# ATmega128RFA1 device description
Architecture: AVR8; Family: megaAVR
Registers are 8-bit, access not given, no defined reset value unless marked. A register's access mark holds for its fields unless they carry their own. Offsets are from the block's base; [hi:lo] are bit positions; 'fields as' and 'values as' point back to an identical list.

## TC1 (TC16 module) — Timer/Counter, 16-bit
Instances: TC1 0x00
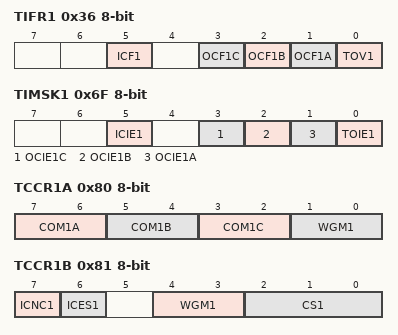
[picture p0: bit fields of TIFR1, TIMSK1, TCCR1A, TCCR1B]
0x36 TIFR1 — Timer/Counter1 Interrupt Flag Register
  [5] ICF1 — Timer/Counter1 Input Capture Flag
  [3] OCF1C — Timer/Counter1 Output Compare C Match Flag
  [2] OCF1B — Timer/Counter1 Output Compare B Match Flag
  [1] OCF1A — Timer/Counter1 Output Compare A Match Flag
  [0] TOV1 — Timer/Counter1 Overflow Flag
0x6F TIMSK1 — Timer/Counter1 Interrupt Mask Register
  [5] ICIE1 — Timer/Counter1 Input Capture Interrupt Enable
  [3] OCIE1C — Timer/Counter1 Output Compare C Match Interrupt Enable
  [2] OCIE1B — Timer/Counter1 Output Compare B Match Interrupt Enable
  [1] OCIE1A — Timer/Counter1 Output Compare A Match Interrupt Enable
  [0] TOIE1 — Timer/Counter1 Overflow Interrupt Enable
0x80 TCCR1A — Timer/Counter1 Control Register A
  [7:6] COM1A — Compare Output Mode for Channel A
    0=Normal port operation, OCnA/OCnB/OCnC disconnected; 1=Toggle OCnA/OCnB/OCnC on Compare Match; 2=Clear OCnA/OCnB/OCnC on Compare Match (set output to low level); 3=Set OCnA/OCnB/OCnC on Compare Match (set output to high level)
  [5:4] COM1B — Compare Output Mode for Channel B
    values as COM1A
  [3:2] COM1C — Compare Output Mode for Channel C
    values as COM1A
  [1:0] WGM1 — Waveform Generation Mode
    0=Normal mode of operation; 1=PWM, phase correct, 8-bit; 2=PWM, phase correct, 9-bit; 3=PWM, phase correct, 10-bit; 4=CTC, TOP = OCRnA; 5=Fast PWM, 8-bit; 6=Fast PWM, 9-bit; 7=Fast PWM, 10-bit; 8=PWM, Phase and frequency correct, TOP = ICRn; 9=PWM, Phase and frequency correct, TOP = OCRnA; 10=PWM, Phase correct, TOP = ICRn; 11=PWM, Phase correct, TOP = OCRnA; 12=CTC, TOP = OCRnA; 14=Fast PWM, TOP = ICRn; 15=Fast PWM, TOP = OCRnA
0x81 TCCR1B — Timer/Counter1 Control Register B
  [7] ICNC1 — Input Capture 1 Noise Canceller
  [6] ICES1 — Input Capture 1 Edge Select
  [4:3] WGM1 (bit 2 of the value upward) — Waveform Generation Mode
    values as TCCR1A.WGM1
  [2:0] CS1 — Clock Select
    0=No clock source (Timer/Counter stopped); 1=clk_IO/1 (no prescaling); 2=clk_IO/8 (from prescaler); 3=clk_IO/64 (from prescaler); 4=clk_IO/256 (from prescaler); 5=clk_IO/1024 (from prescaler); 6=External clock source on Tn pin, clock on falling edge; 7=External clock source on Tn pin, clock on rising edge
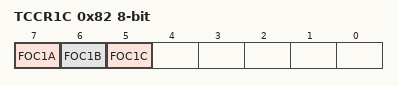
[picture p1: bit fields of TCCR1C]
0x82 TCCR1C — Timer/Counter1 Control Register C
  [7] FOC1A — Force Output Compare for Channel A
  [6] FOC1B — Force Output Compare for Channel B
  [5] FOC1C — Force Output Compare for Channel C
0x84 TCNT1 16-bit — Timer/Counter1 Bytes
0x86 ICR1 16-bit — Timer/Counter1 Input Capture Register Bytes
0x88 OCR1A 16-bit — Timer/Counter1 Output Compare Register A Bytes
0x8A OCR1B 16-bit — Timer/Counter1 Output Compare Register B Bytes
0x8C OCR1C 16-bit — Timer/Counter1 Output Compare Register C Bytes

## SYMCNT — MAC Symbol Counter
Instances: SYMCNT 0x00
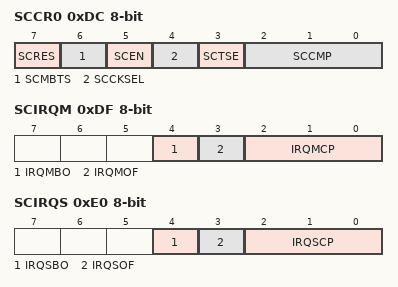
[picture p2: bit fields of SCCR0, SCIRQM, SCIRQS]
0xDC SCCR0 — Symbol Counter Control Register 0
  [7] SCRES — Symbol Counter Synchronization
  [6] SCMBTS — Manual Beacon Timestamp
  [5] SCEN — Symbol Counter enable
  [4] SCCKSEL — Symbol Counter Clock Source select
  [3] SCTSE — Symbol Counter Automatic Timestamping enable
  [2:0] SCCMP (bit 1 of the value upward) — Symbol Counter Compare Unit 3 Mode select
0xDD SCCR1 — Symbol Counter Control Register 1
  [0] SCENBO — Backoff Slot Counter enable
0xDE SCSR — Symbol Counter Status Register
  [0] SCBSY — Symbol Counter busy
0xDF SCIRQM — Symbol Counter Interrupt Mask Register
  [4] IRQMBO — Backoff Slot Counter IRQ enable
  [3] IRQMOF — Symbol Counter Overflow IRQ enable
  [2:0] IRQMCP (bit 1 of the value upward) — Symbol Counter Compare Match 3 IRQ enable
0xE0 SCIRQS — Symbol Counter Interrupt Status Register
  [4] IRQSBO — Backoff Slot Counter IRQ
  [3] IRQSOF — Symbol Counter Overflow IRQ
  [2:0] IRQSCP (bit 1 of the value upward) — Compare Unit 3 Compare Match IRQ
0xE1 SCCNTLL — Symbol Counter Register LL-Byte
0xE2 SCCNTLH — Symbol Counter Register LH-Byte
0xE3 SCCNTHL — Symbol Counter Register HL-Byte
0xE4 SCCNTHH — Symbol Counter Register HH-Byte
0xE5 SCBTSRLL — Symbol Counter Beacon Timestamp Register LL-Byte
0xE6 SCBTSRLH — Symbol Counter Beacon Timestamp Register LH-Byte
0xE7 SCBTSRHL — Symbol Counter Beacon Timestamp Register HL-Byte
0xE8 SCBTSRHH — Symbol Counter Beacon Timestamp Register HH-Byte
0xE9 SCTSRLL — Symbol Counter Frame Timestamp Register LL-Byte
0xEA SCTSRLH — Symbol Counter Frame Timestamp Register LH-Byte
0xEB SCTSRHL — Symbol Counter Frame Timestamp Register HL-Byte
0xEC SCTSRHH — Symbol Counter Frame Timestamp Register HH-Byte
0xED SCOCR3LL — Symbol Counter Output Compare Register 3 LL-Byte
0xEE SCOCR3LH — Symbol Counter Output Compare Register 3 LH-Byte
0xEF SCOCR3HL — Symbol Counter Output Compare Register 3 HL-Byte
0xF0 SCOCR3HH — Symbol Counter Output Compare Register 3 HH-Byte
0xF1 SCOCR2LL — Symbol Counter Output Compare Register 2 LL-Byte
0xF2 SCOCR2LH — Symbol Counter Output Compare Register 2 LH-Byte
0xF3 SCOCR2HL — Symbol Counter Output Compare Register 2 HL-Byte
0xF4 SCOCR2HH — Symbol Counter Output Compare Register 2 HH-Byte
0xF5 SCOCR1LL — Symbol Counter Output Compare Register 1 LL-Byte
0xF6 SCOCR1LH — Symbol Counter Output Compare Register 1 LH-Byte
0xF7 SCOCR1HL — Symbol Counter Output Compare Register 1 HL-Byte
0xF8 SCOCR1HH — Symbol Counter Output Compare Register 1 HH-Byte
